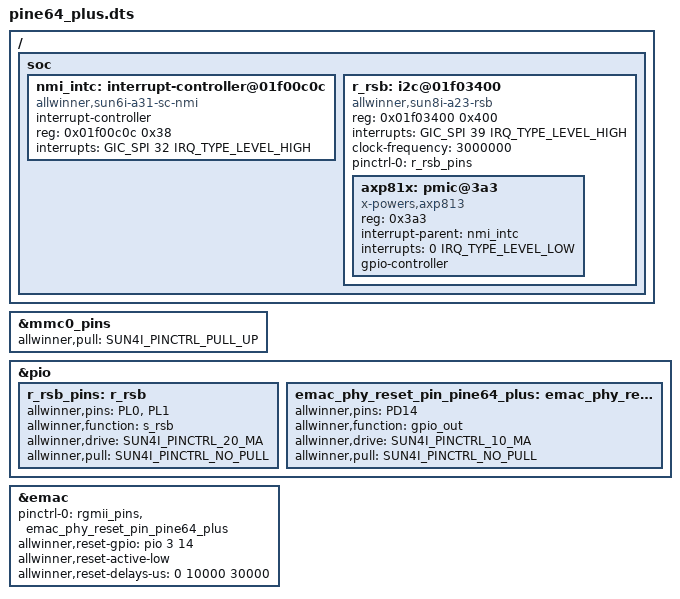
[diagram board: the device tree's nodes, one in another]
/*-
 * Copyright (c) 2016 Jared McNeill <jmcneill@invisible.ca>
 * All rights reserved.
 *
 * Redistribution and use in source and binary forms, with or without
 * modification, are permitted provided that the following conditions
 * are met:
 * 1. Redistributions of source code must retain the above copyright
 *    notice, this list of conditions and the following disclaimer.
 * 2. Redistributions in binary form must reproduce the above copyright
 *    notice, this list of conditions and the following disclaimer in the
 *    documentation and/or other materials provided with the distribution.
 *
 * THIS SOFTWARE IS PROVIDED BY THE AUTHOR AND CONTRIBUTORS ``AS IS'' AND
 * ANY EXPRESS OR IMPLIED WARRANTIES, INCLUDING, BUT NOT LIMITED TO, THE
 * IMPLIED WARRANTIES OF MERCHANTABILITY AND FITNESS FOR A PARTICULAR PURPOSE
 * ARE DISCLAIMED.  IN NO EVENT SHALL THE AUTHOR OR CONTRIBUTORS BE LIABLE
 * FOR ANY DIRECT, INDIRECT, INCIDENTAL, SPECIAL, EXEMPLARY, OR CONSEQUENTIAL
 * DAMAGES (INCLUDING, BUT NOT LIMITED TO, PROCUREMENT OF SUBSTITUTE GOODS
 * OR SERVICES; LOSS OF USE, DATA, OR PROFITS; OR BUSINESS INTERRUPTION)
 * HOWEVER CAUSED AND ON ANY THEORY OF LIABILITY, WHETHER IN CONTRACT, STRICT
 * LIABILITY, OR TORT (INCLUDING NEGLIGENCE OR OTHERWISE) ARISING IN ANY WAY
 * OUT OF THE USE OF THIS SOFTWARE, EVEN IF ADVISED OF THE POSSIBILITY OF
 * SUCH DAMAGE.
 *
 * $FreeBSD$
 */

#include "sun50i-a64-pine64-plus.dts"

#include <dt-bindings/gpio/gpio.h>

&mmc0_pins {
	allwinner,pull = <SUN4I_PINCTRL_PULL_UP>;
};

/ {
	soc {
		nmi_intc: interrupt-controller@01f00c0c {
			compatible = "allwinner,sun6i-a31-sc-nmi";
			interrupt-controller;
			#interrupt-cells = <2>;
			reg = <0x01f00c0c 0x38>;
			interrupts = <GIC_SPI 32 IRQ_TYPE_LEVEL_HIGH>;
		};

		r_rsb: i2c@01f03400 {
			compatible = "allwinner,sun8i-a23-rsb";
			reg = <0x01f03400 0x400>;
			interrupts = <GIC_SPI 39 IRQ_TYPE_LEVEL_HIGH>;
			clock-frequency = <3000000>;
			pinctrl-names = "default";
			pinctrl-0 = <&r_rsb_pins>;
			status = "disabled";
			#address-cells = <1>;
			#size-cells = <0>;
		};
	};
};

&pio {
	r_rsb_pins: r_rsb {
		allwinner,pins = "PL0", "PL1";
		allwinner,function = "s_rsb";
		allwinner,drive = <SUN4I_PINCTRL_20_MA>;
		allwinner,pull = <SUN4I_PINCTRL_NO_PULL>;
	};

	emac_phy_reset_pin_pine64_plus: emac_phy_reset_pin@0 {
		allwinner,pins = "PD14";
		allwinner,function = "gpio_out";
		allwinner,drive = <SUN4I_PINCTRL_10_MA>;
		allwinner,pull = <SUN4I_PINCTRL_NO_PULL>;
	};
};

&emac {
	pinctrl-names = "default";
	pinctrl-0 = <&rgmii_pins>, <&emac_phy_reset_pin_pine64_plus>;

	allwinner,reset-gpio = <&pio 3 14 GPIO_ACTIVE_HIGH>;
	allwinner,reset-active-low;
	allwinner,reset-delays-us = <0 10000 30000>;
};

&r_rsb {
	status = "okay";

	axp81x: pmic@3a3 {
		compatible = "x-powers,axp813";
		reg = <0x3a3>;
		interrupt-parent = <&nmi_intc>;
		interrupts = <0 IRQ_TYPE_LEVEL_LOW>;
		gpio-controller;
		#gpio-cells = <1>;
	};
};
